# STM32F405RGT6 register map
Vendor: STMicroelectronics; File version: 0.1.0
CPU: Cortex-M4 r0p1, little endian, MPU, FPU, DSP, VTOR, 4 interrupt priority bits
Registers are 32-bit, read-write, reset 0x0 unless marked. A register's access mark holds for its fields unless they carry their own. Offsets are from the block's base; [hi:lo] are bit positions; {n}, {i} and the like mark numbered series; 'fields as' and 'values as' point back to an identical list.

## RTC — Real-time clock
Base 0x40002800
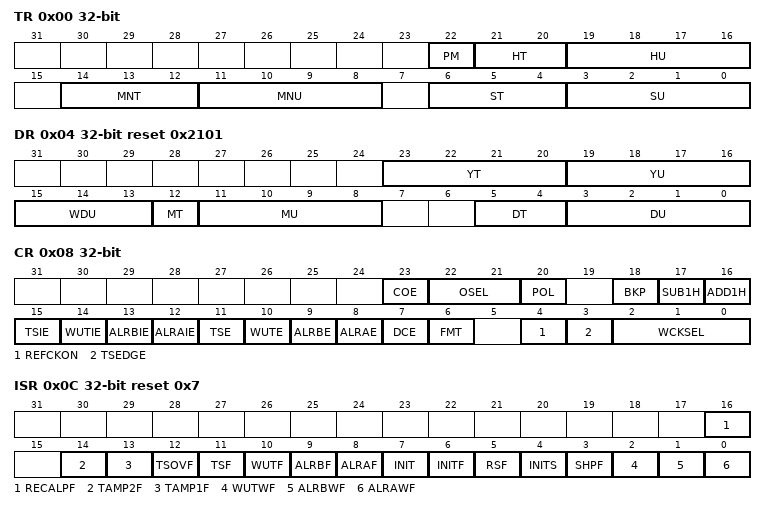
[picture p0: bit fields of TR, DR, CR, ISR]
0x00 TR — time register
  [22] PM — AM/PM notation
  [21:20] HT — Hour tens in BCD format
  [19:16] HU — Hour units in BCD format
  [14:12] MNT — Minute tens in BCD format
  [11:8] MNU — Minute units in BCD format
  [6:4] ST — Second tens in BCD format
  [3:0] SU — Second units in BCD format
0x04 DR reset 0x2101 — date register
  [23:20] YT — Year tens in BCD format
  [19:16] YU — Year units in BCD format
  [15:13] WDU — Week day units
  [12] MT — Month tens in BCD format
  [11:8] MU — Month units in BCD format
  [5:4] DT — Date tens in BCD format
  [3:0] DU — Date units in BCD format
0x08 CR — control register
  [23] COE — Calibration output enable
  [22:21] OSEL — Output selection
  [20] POL — Output polarity
  [18] BKP — Backup
  [17] SUB1H — Subtract 1 hour (winter time change)
  [16] ADD1H — Add 1 hour (summer time change)
  [15] TSIE — Time-stamp interrupt enable
  [14] WUTIE — Wakeup timer interrupt enable
  [13] ALRBIE — Alarm B interrupt enable
  [12] ALRAIE — Alarm A interrupt enable
  [11] TSE — Time stamp enable
  [10] WUTE — Wakeup timer enable
  [9] ALRBE — Alarm B enable
  [8] ALRAE — Alarm A enable
  [7] DCE — Coarse digital calibration enable
  [6] FMT — Hour format
  [4] REFCKON — Reference clock detection enable (50 or 60 Hz)
  [3] TSEDGE — Time-stamp event active edge
  [2:0] WCKSEL — Wakeup clock selection
0x0C ISR access per field reset 0x7 — initialization and status register
  [16] RECALPF ro — Recalibration pending Flag
  [14] TAMP2F rw — TAMPER2 detection flag
  [13] TAMP1F rw — Tamper detection flag
  [12] TSOVF rw — Time-stamp overflow flag
  [11] TSF rw — Time-stamp flag
  [10] WUTF rw — Wakeup timer flag
  [9] ALRBF rw — Alarm B flag
  [8] ALRAF rw — Alarm A flag
  [7] INIT rw — Initialization mode
  [6] INITF ro — Initialization flag
  [5] RSF rw — Registers synchronization flag
  [4] INITS ro — Initialization status flag
  [3] SHPF rw — Shift operation pending
  [2] WUTWF ro — Wakeup timer write flag
  [1] ALRBWF ro — Alarm B write flag
  [0] ALRAWF ro — Alarm A write flag
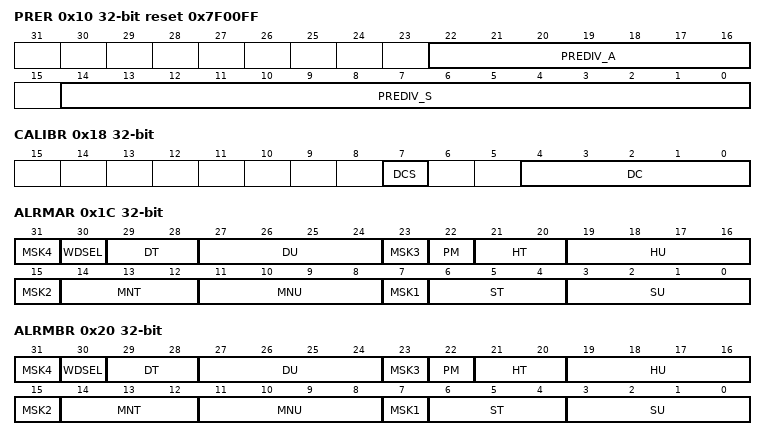
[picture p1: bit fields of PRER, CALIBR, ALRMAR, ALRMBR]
0x10 PRER reset 0x7F00FF — prescaler register
  [22:16] PREDIV_A — Asynchronous prescaler factor
  [14:0] PREDIV_S — Synchronous prescaler factor
0x14 WUTR reset 0xFFFF — wakeup timer register
  [15:0] WUT — Wakeup auto-reload value bits
0x18 CALIBR — calibration register
  [7] DCS — Digital calibration sign
  [4:0] DC — Digital calibration
0x1C ALRMAR — alarm A register
  [31] MSK4 — Alarm A date mask
  [30] WDSEL — Week day selection
  [29:28] DT — Date tens in BCD format
  [27:24] DU — Date units or day in BCD format
  [23] MSK3 — Alarm A hours mask
  [22] PM — AM/PM notation
  [21:20] HT — Hour tens in BCD format
  [19:16] HU — Hour units in BCD format
  [15] MSK2 — Alarm A minutes mask
  [14:12] MNT — Minute tens in BCD format
  [11:8] MNU — Minute units in BCD format
  [7] MSK1 — Alarm A seconds mask
  [6:4] ST — Second tens in BCD format
  [3:0] SU — Second units in BCD format
0x20 ALRMBR — alarm B register
  [31] MSK4 — Alarm B date mask
  [30] WDSEL — Week day selection
  [29:28] DT — Date tens in BCD format
  [27:24] DU — Date units or day in BCD format
  [23] MSK3 — Alarm B hours mask
  [22] PM — AM/PM notation
  [21:20] HT — Hour tens in BCD format
  [19:16] HU — Hour units in BCD format
  [15] MSK2 — Alarm B minutes mask
  [14:12] MNT — Minute tens in BCD format
  [11:8] MNU — Minute units in BCD format
  [7] MSK1 — Alarm B seconds mask
  [6:4] ST — Second tens in BCD format
  [3:0] SU — Second units in BCD format
0x24 WPR wo — write protection register
  [7:0] KEY — Write protection key
0x28 SSR ro — sub second register
  [15:0] SS — Sub second value
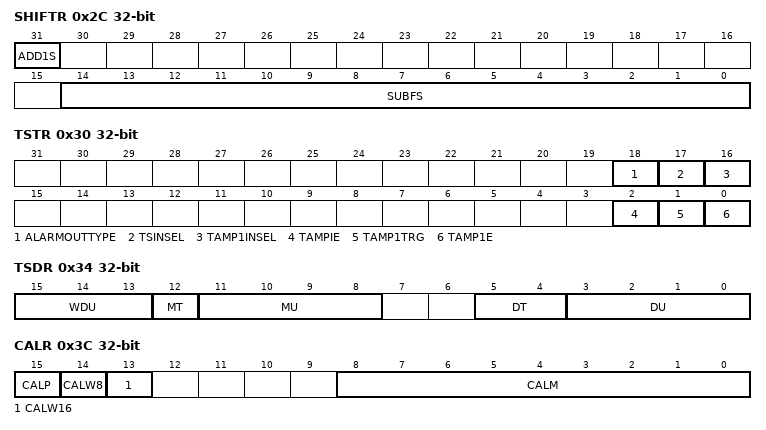
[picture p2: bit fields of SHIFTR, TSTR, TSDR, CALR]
0x2C SHIFTR wo — shift control register
  [31] ADD1S — Add one second
  [14:0] SUBFS — Subtract a fraction of a second
0x30 TSTR ro — time stamp time register
  [18] ALARMOUTTYPE — AFO_ALARM output type
  [17] TSINSEL — TIMESTAMP mapping
  [16] TAMP1INSEL — TAMPER1 mapping
  [2] TAMPIE — Tamper interrupt enable
  [1] TAMP1TRG — Active level for tamper 1
  [0] TAMP1E — Tamper 1 detection enable
0x34 TSDR ro — time stamp date register
  [15:13] WDU — Week day units
  [12] MT — Month tens in BCD format
  [11:8] MU — Month units in BCD format
  [5:4] DT — Date tens in BCD format
  [3:0] DU — Date units in BCD format
0x38 TSSSR ro — timestamp sub second register
  [15:0] SS — Sub second value
0x3C CALR — calibration register
  [15] CALP — Increase frequency of RTC by 488.5 ppm
  [14] CALW8 — Use an 8-second calibration cycle period
  [13] CALW16 — Use a 16-second calibration cycle period
  [8:0] CALM — Calibration minus
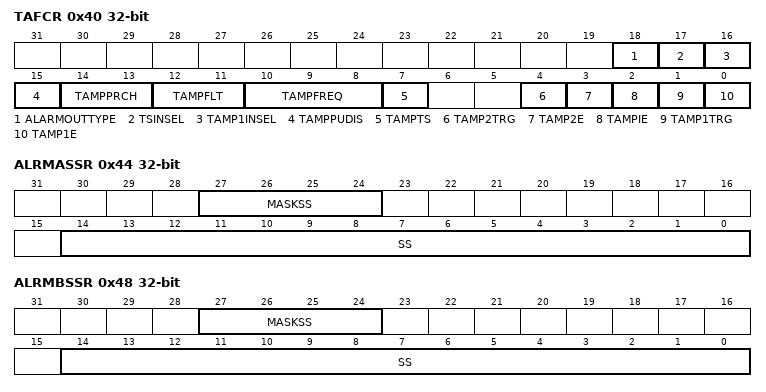
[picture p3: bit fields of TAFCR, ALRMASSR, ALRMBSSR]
0x40 TAFCR — tamper and alternate function configuration register
  [18] ALARMOUTTYPE — AFO_ALARM output type
  [17] TSINSEL — TIMESTAMP mapping
  [16] TAMP1INSEL — TAMPER1 mapping
  [15] TAMPPUDIS — TAMPER pull-up disable
  [14:13] TAMPPRCH — Tamper precharge duration
  [12:11] TAMPFLT — Tamper filter count
  [10:8] TAMPFREQ — Tamper sampling frequency
  [7] TAMPTS — Activate timestamp on tamper detection event
  [4] TAMP2TRG — Active level for tamper 2
  [3] TAMP2E — Tamper 2 detection enable
  [2] TAMPIE — Tamper interrupt enable
  [1] TAMP1TRG — Active level for tamper 1
  [0] TAMP1E — Tamper 1 detection enable
0x44 ALRMASSR — alarm A sub second register
  [27:24] MASKSS — Mask the most-significant bits starting at this bit
  [14:0] SS — Sub seconds value
0x48 ALRMBSSR — alarm B sub second register
  fields as ALRMASSR
{0x50+4i} BKP{i}R (i=0..19) — backup register
  [31:0] BKP
